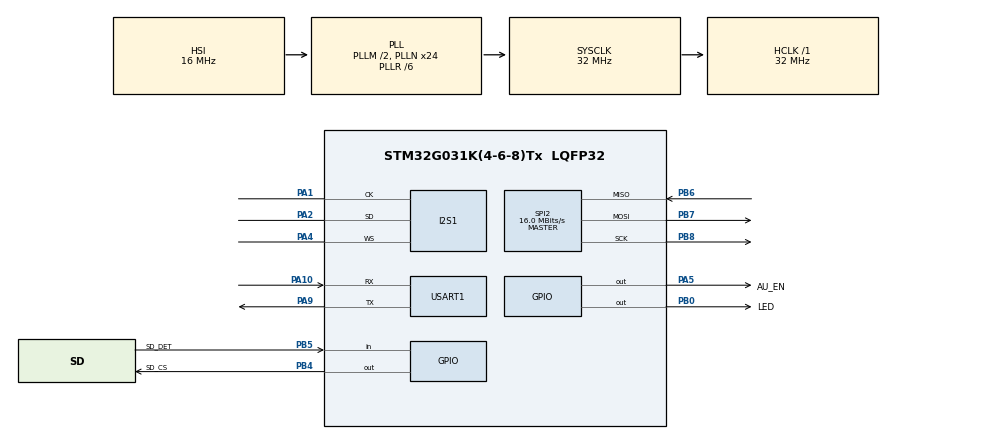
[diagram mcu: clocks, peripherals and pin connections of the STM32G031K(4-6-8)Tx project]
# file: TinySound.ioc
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Dma.Request0=SPI1_TX
Dma.Request1=USART1_RX
Dma.Request2=SPI2_RX
Dma.Request3=SPI2_TX
Dma.SPI1_TX.0.Direction=DMA_MEMORY_TO_PERIPH
Dma.SPI1_TX.0.EventEnable=DISABLE
Dma.SPI1_TX.0.Instance=DMA1_Channel1
Dma.SPI1_TX.0.MemDataAlignment=DMA_MDATAALIGN_HALFWORD
Dma.SPI1_TX.0.MemInc=DMA_MINC_ENABLE
Dma.SPI1_TX.0.Mode=DMA_CIRCULAR
Dma.SPI1_TX.0.PeriphDataAlignment=DMA_PDATAALIGN_HALFWORD
Dma.SPI1_TX.0.PeriphInc=DMA_PINC_DISABLE
Dma.SPI1_TX.0.Polarity=HAL_DMAMUX_REQ_GEN_RISING
Dma.SPI1_TX.0.Priority=DMA_PRIORITY_VERY_HIGH
Dma.SPI1_TX.0.RequestNumber=1
Dma.SPI1_TX.0.SignalID=NONE
Dma.SPI1_TX.0.SyncEnable=DISABLE
Dma.SPI1_TX.0.SyncPolarity=HAL_DMAMUX_SYNC_NO_EVENT
Dma.SPI1_TX.0.SyncRequestNumber=1
Dma.SPI1_TX.0.SyncSignalID=NONE
Dma.SPI2_RX.2.Direction=DMA_PERIPH_TO_MEMORY
Dma.SPI2_RX.2.EventEnable=DISABLE
Dma.SPI2_RX.2.Instance=DMA1_Channel3
Dma.SPI2_RX.2.MemDataAlignment=DMA_MDATAALIGN_BYTE
Dma.SPI2_RX.2.MemInc=DMA_MINC_ENABLE
Dma.SPI2_RX.2.Mode=DMA_NORMAL
Dma.SPI2_RX.2.PeriphDataAlignment=DMA_PDATAALIGN_BYTE
Dma.SPI2_RX.2.PeriphInc=DMA_PINC_DISABLE
Dma.SPI2_RX.2.Polarity=HAL_DMAMUX_REQ_GEN_RISING
Dma.SPI2_RX.2.Priority=DMA_PRIORITY_HIGH
Dma.SPI2_RX.2.RequestNumber=1
Dma.SPI2_RX.2.SignalID=NONE
Dma.SPI2_RX.2.SyncEnable=DISABLE
Dma.SPI2_RX.2.SyncPolarity=HAL_DMAMUX_SYNC_NO_EVENT
Dma.SPI2_RX.2.SyncRequestNumber=1
Dma.SPI2_RX.2.SyncSignalID=NONE
Dma.SPI2_TX.3.Direction=DMA_MEMORY_TO_PERIPH
Dma.SPI2_TX.3.EventEnable=DISABLE
Dma.SPI2_TX.3.Instance=DMA1_Channel4
Dma.SPI2_TX.3.MemDataAlignment=DMA_MDATAALIGN_BYTE
Dma.SPI2_TX.3.MemInc=DMA_MINC_DISABLE
Dma.SPI2_TX.3.Mode=DMA_NORMAL
Dma.SPI2_TX.3.PeriphDataAlignment=DMA_PDATAALIGN_BYTE
Dma.SPI2_TX.3.PeriphInc=DMA_PINC_DISABLE
Dma.SPI2_TX.3.Polarity=HAL_DMAMUX_REQ_GEN_RISING
Dma.SPI2_TX.3.Priority=DMA_PRIORITY_HIGH
Dma.SPI2_TX.3.RequestNumber=1
Dma.SPI2_TX.3.SignalID=NONE
Dma.SPI2_TX.3.SyncEnable=DISABLE
Dma.SPI2_TX.3.SyncPolarity=HAL_DMAMUX_SYNC_NO_EVENT
Dma.SPI2_TX.3.SyncRequestNumber=1
Dma.SPI2_TX.3.SyncSignalID=NONE
Dma.USART1_RX.1.Direction=DMA_PERIPH_TO_MEMORY
Dma.USART1_RX.1.EventEnable=DISABLE
Dma.USART1_RX.1.Instance=DMA1_Channel2
Dma.USART1_RX.1.MemDataAlignment=DMA_MDATAALIGN_BYTE
Dma.USART1_RX.1.MemInc=DMA_MINC_ENABLE
Dma.USART1_RX.1.Mode=DMA_NORMAL
Dma.USART1_RX.1.PeriphDataAlignment=DMA_PDATAALIGN_BYTE
Dma.USART1_RX.1.PeriphInc=DMA_PINC_DISABLE
Dma.USART1_RX.1.Polarity=HAL_DMAMUX_REQ_GEN_RISING
Dma.USART1_RX.1.Priority=DMA_PRIORITY_LOW
Dma.USART1_RX.1.RequestNumber=1
Dma.USART1_RX.1.SignalID=NONE
Dma.USART1_RX.1.SyncEnable=DISABLE
Dma.USART1_RX.1.SyncPolarity=HAL_DMAMUX_SYNC_NO_EVENT
Dma.USART1_RX.1.SyncRequestNumber=1
Dma.USART1_RX.1.SyncSignalID=NONE
FATFS._LFN_UNICODE=0
FATFS._STRF_ENCODE=0
FATFS._USE_FORWARD=0
FATFS._USE_LFN=2
FATFS._USE_MKFS=0
FATFS._USE_STRFUNC=1
I2S1.AudioFreq=I2S_AUDIOFREQ_48K
I2S1.ErrorAudioFreq=0.0 %
I2S1.FullDuplexMode=I2S_FULLDUPLEXMODE_DISABLE
I2S1.Instance=SPI$Index
I2S1.RealAudioFreq=48.0 KHz
I2S1.VirtualMode=I2S_MODE_MASTER
Mcu.Family=STM32G0
Mcu.Name=STM32G031K(4-6-8)Tx
Mcu.Package=LQFP32
NVIC.DMA1_Ch4_5_DMAMUX1_OVR_IRQn=true\:0\:0\:false\:false\:true\:false\:true
NVIC.DMA1_Channel1_IRQn=true\:0\:0\:false\:false\:true\:false\:true
NVIC.DMA1_Channel2_3_IRQn=true\:0\:0\:false\:false\:true\:false\:true
PA0.Mode=SYS_WakeUp0
PA0.Signal=SYS_WKUP1
PA1.Mode=Half_Duplex_Master
PA1.Signal=I2S1_CK
PA10.Mode=Asynchronous
PA10.Signal=USART1_RX
PA13.Mode=Serial_Wire
PA13.Signal=SYS_SWDIO
PA14-BOOT0.Mode=Serial_Wire
PA14-BOOT0.Signal=SYS_SWCLK
PA2.Mode=Half_Duplex_Master
PA2.Signal=I2S1_SD
PA4.Mode=Half_Duplex_Master
PA4.Signal=I2S1_WS
PA5.GPIO_Label=AU_EN
PA5.Signal=GPIO_Output
PA9.Mode=Asynchronous
PA9.Signal=USART1_TX
PB0.GPIO_Label=LED
PB0.Signal=GPIO_Output
PB4.GPIO_Label=SD_CS
PB4.Signal=GPIO_Output
PB5.GPIO_Label=SD_DET
PB5.Signal=GPIO_Input
PB6.Mode=Full_Duplex_Master
PB6.Signal=SPI2_MISO
PB7.Mode=Full_Duplex_Master
PB7.Signal=SPI2_MOSI
PB8.Mode=Full_Duplex_Master
PB8.Signal=SPI2_SCK
ProjectManager.HeapSize=0x200
ProjectManager.StackSize=0x400
ProjectManager.TargetToolchain=Makefile
RCC.ADCFreq_Value=32000000
RCC.AHBFreq_Value=32000000
RCC.CortexFreq_Value=32000000
RCC.EXTERNAL_CLOCK_VALUE=12288000
RCC.HCLKFreq_Value=32000000
RCC.HSE_VALUE=8000000
RCC.HSI_VALUE=16000000
RCC.I2S1CLockSelection=RCC_I2S1CLKSOURCE_PLL
RCC.LSE_VALUE=32768
RCC.PLLM=RCC_PLLM_DIV2
RCC.PLLN=24
RCC.PLLP=RCC_PLLP_DIV5
RCC.PLLR=RCC_PLLR_DIV6
RCC.SYSCLKFreq_VALUE=32000000
RCC.SYSCLKSource=RCC_SYSCLKSOURCE_PLLCLK
RCC.USART1CLockSelection=RCC_USART1CLKSOURCE_SYSCLK
RCC.VCOOutputFreq_Value=192000000
SPI2.BaudRatePrescaler=SPI_BAUDRATEPRESCALER_2
SPI2.CalculateBaudRate=16.0 MBits/s
SPI2.Direction=SPI_DIRECTION_2LINES
SPI2.Mode=SPI_MODE_MASTER
SPI2.VirtualType=VM_MASTER
USART1.VirtualMode-Asynchronous=VM_ASYNC
VP_FATFS_VS_Generic.Mode=User_defined
board=custom

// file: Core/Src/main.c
/* USER CODE BEGIN Header */
/**
  ******************************************************************************
  * @file           : main.c
  * @brief          : Main program body
  ******************************************************************************
  * @attention
  *
  * <h2><center>&copy; Copyright (c) 2021 STMicroelectronics.
  * All rights reserved.</center></h2>
  *
  * This software component is licensed by ST under Ultimate Liberty license
  * SLA0044, the "License"; You may not use this file except in compliance with
  * the License. You may obtain a copy of the License at:
  *                             www.st.com/SLA0044
  *
  ******************************************************************************
  */
/* USER CODE END Header */
#include "main.h"
#include "dma.h"
#include "app_fatfs.h"
#include "i2s.h"
#include "spi.h"
#include "usart.h"
#include "gpio.h"

/* USER CODE BEGIN Includes */
#include "shell.h"
#include "audio.h"
/* USER CODE END Includes */

void SystemClock_Config(void);

int main(void)
{

  /* MCU Configuration--------------------------------------------------------*/

  /* Reset of all peripherals, Initializes the Flash interface and the Systick. */
  HAL_Init();

  /* Configure the system clock */
  SystemClock_Config();

  /* Initialize all configured peripherals */
  MX_GPIO_Init();
  MX_DMA_Init();
  MX_I2S1_Init();
  MX_SPI2_Init();
  MX_USART1_UART_Init();
  if (MX_FATFS_Init() != APP_OK) {
    Error_Handler();
  }
  /* USER CODE BEGIN 2 */

  Shell_Init();
  /* USER CODE END 2 */

  /* Infinite loop */
  while (1)
  {

    /* USER CODE BEGIN 3 */
    Shell_CheckCommand();
    Audio_CheckEvents();
  }
  /* USER CODE END 3 */
}

void SystemClock_Config(void)
{
  RCC_OscInitTypeDef RCC_OscInitStruct = {0};
  RCC_ClkInitTypeDef RCC_ClkInitStruct = {0};
  RCC_PeriphCLKInitTypeDef PeriphClkInit = {0};

  /** Configure the main internal regulator output voltage
  */
  HAL_PWREx_ControlVoltageScaling(PWR_REGULATOR_VOLTAGE_SCALE1);
  /** Initializes the RCC Oscillators according to the specified parameters
  * in the RCC_OscInitTypeDef structure.
  */
  RCC_OscInitStruct.OscillatorType = RCC_OSCILLATORTYPE_HSI;
  RCC_OscInitStruct.HSIState = RCC_HSI_ON;
  RCC_OscInitStruct.HSIDiv = RCC_HSI_DIV1;
  RCC_OscInitStruct.HSICalibrationValue = RCC_HSICALIBRATION_DEFAULT;
  RCC_OscInitStruct.PLL.PLLState = RCC_PLL_ON;
  RCC_OscInitStruct.PLL.PLLSource = RCC_PLLSOURCE_HSI;
  RCC_OscInitStruct.PLL.PLLM = RCC_PLLM_DIV2;
  RCC_OscInitStruct.PLL.PLLN = 24;
  RCC_OscInitStruct.PLL.PLLP = RCC_PLLP_DIV5;
  RCC_OscInitStruct.PLL.PLLQ = RCC_PLLQ_DIV2;
  RCC_OscInitStruct.PLL.PLLR = RCC_PLLR_DIV6;
  if (HAL_RCC_OscConfig(&RCC_OscInitStruct) != HAL_OK)
  {
    Error_Handler();
  }
  /** Initializes the CPU, AHB and APB buses clocks
  */
  RCC_ClkInitStruct.ClockType = RCC_CLOCKTYPE_HCLK|RCC_CLOCKTYPE_SYSCLK
                              |RCC_CLOCKTYPE_PCLK1;
  RCC_ClkInitStruct.SYSCLKSource = RCC_SYSCLKSOURCE_PLLCLK;
  RCC_ClkInitStruct.AHBCLKDivider = RCC_SYSCLK_DIV1;
  RCC_ClkInitStruct.APB1CLKDivider = RCC_HCLK_DIV1;

  if (HAL_RCC_ClockConfig(&RCC_ClkInitStruct, FLASH_LATENCY_1) != HAL_OK)
  {
    Error_Handler();
  }
  /** Initializes the peripherals clocks
  */
  PeriphClkInit.PeriphClockSelection = RCC_PERIPHCLK_USART1|RCC_PERIPHCLK_I2S1;
  PeriphClkInit.Usart1ClockSelection = RCC_USART1CLKSOURCE_SYSCLK;
  PeriphClkInit.I2s1ClockSelection = RCC_I2S1CLKSOURCE_PLL;
  if (HAL_RCCEx_PeriphCLKConfig(&PeriphClkInit) != HAL_OK)
  {
    Error_Handler();
  }
}

void Error_Handler(void)
{
  /* USER CODE BEGIN Error_Handler_Debug */
  /* User can add his own implementation to report the HAL error return state */
  while(1)
  {
    HAL_GPIO_WritePin(LED_GPIO_Port, LED_Pin, GPIO_PIN_SET);
    HAL_Delay(50);
    HAL_GPIO_WritePin(LED_GPIO_Port, LED_Pin, GPIO_PIN_RESET);
    HAL_Delay(50);
  }
  /* USER CODE END Error_Handler_Debug */
}

/************************ (C) COPYRIGHT STMicroelectronics *****END OF FILE****/
